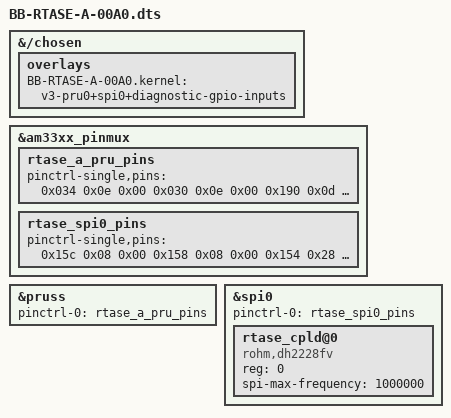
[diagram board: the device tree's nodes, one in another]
/*
 * RTASE_V1 channel-A PRU0 pinmux (AM335x, 3-cell pinctrl format).
 *
 * P8_11: R30.15 -> SYM.A0
 * P8_12: R30.14 -> SYM.A1
 * P9_31: R30.0  -> LDAC.A (CPLD forwards this to AD9744 D1CLK)
 *
 * conf 0x08 means no pull and output enabled; mux modes are 6, 6 and 5.
 */
/dts-v1/;
/plugin/;

&{/chosen} {
	overlays {
		BB-RTASE-A-00A0.kernel = "v3-pru0+spi0+diagnostic-gpio-inputs";
	};
};

&am33xx_pinmux {
	rtase_a_pru_pins: rtase_a_pru_pins {
		pinctrl-single,pins = <
			0x034 0x0e 0x00  /* P8_11 -> PRU0 R30.15, mode 6 */
			0x030 0x0e 0x00  /* P8_12 -> PRU0 R30.14, mode 6 */
			0x190 0x0d 0x00  /* P9_31 -> PRU0 R30.0,  mode 5 */
			0x024 0x27 0x00  /* P8_13 -> GPIO0_23 input, CS seen */
			0x028 0x27 0x00  /* P8_14 -> GPIO0_26 input, SCLK seen */
			0x03c 0x27 0x00  /* P8_15 -> GPIO1_15 input, write done */
			0x038 0x27 0x00  /* P8_16 -> GPIO1_14 input, frame done */
			0x08c 0x27 0x00  /* P8_18 -> GPIO2_1 input, image alive */
		>;
	};

	rtase_spi0_pins: rtase_spi0_pins {
		pinctrl-single,pins = <
			0x15c 0x08 0x00  /* P9_17 -> SPI0_CS0, output */
			0x158 0x08 0x00  /* P9_18 -> SPI0_D1/MOSI, output */
			0x154 0x28 0x00  /* P9_21 -> SPI0_D0/MISO, input */
			0x150 0x08 0x00  /* P9_22 -> SPI0_SCLK, output */
		>;
	};
};

&pruss {
	status = "okay";
	pinctrl-names = "default";
	pinctrl-0 = <&rtase_a_pru_pins>;
};

&spi0 {
	status = "okay";
	pinctrl-names = "default";
	pinctrl-0 = <&rtase_spi0_pins>;

	rtase_cpld@0 {
		compatible = "rohm,dh2228fv";
		reg = <0>;
		spi-max-frequency = <1000000>;
	};
};
